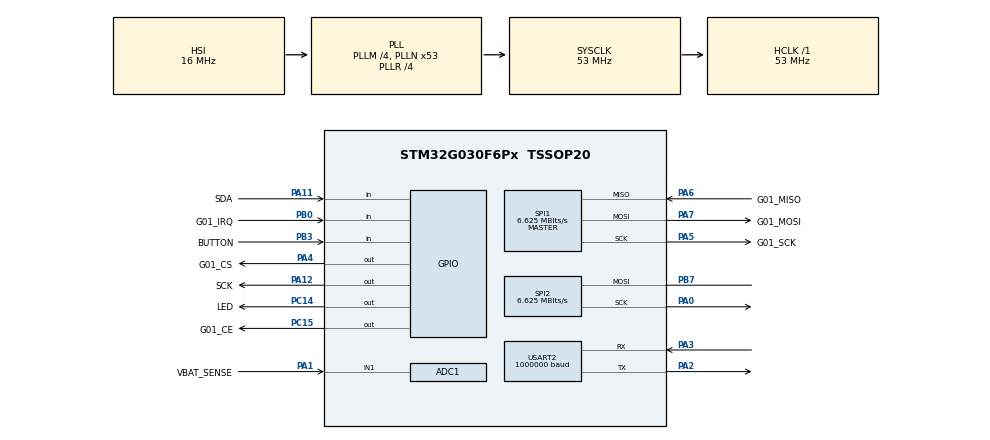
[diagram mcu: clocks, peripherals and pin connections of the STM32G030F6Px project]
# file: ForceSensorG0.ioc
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ADC1.Channel-1\#ChannelRegularConversion=ADC_CHANNEL_1
ADC1.NbrOfConversionFlag=1
ADC1.Rank-1\#ChannelRegularConversion=1
ADC1.SamplingTime-1\#ChannelRegularConversion=ADC_SAMPLINGTIME_COMMON_1
ADC1.SelectedChannel=ADC_CHANNEL_1
ADC1.master=1
Dma.Request0=SPI2_TX
Dma.Request1=SPI1_TX
Dma.SPI1_TX.1.Direction=DMA_MEMORY_TO_PERIPH
Dma.SPI1_TX.1.EventEnable=DISABLE
Dma.SPI1_TX.1.Instance=DMA1_Channel2
Dma.SPI1_TX.1.MemDataAlignment=DMA_MDATAALIGN_BYTE
Dma.SPI1_TX.1.MemInc=DMA_MINC_ENABLE
Dma.SPI1_TX.1.Mode=DMA_NORMAL
Dma.SPI1_TX.1.PeriphDataAlignment=DMA_PDATAALIGN_BYTE
Dma.SPI1_TX.1.PeriphInc=DMA_PINC_DISABLE
Dma.SPI1_TX.1.Polarity=HAL_DMAMUX_REQ_GEN_RISING
Dma.SPI1_TX.1.Priority=DMA_PRIORITY_LOW
Dma.SPI1_TX.1.RequestNumber=1
Dma.SPI1_TX.1.SignalID=NONE
Dma.SPI1_TX.1.SyncEnable=DISABLE
Dma.SPI1_TX.1.SyncPolarity=HAL_DMAMUX_SYNC_NO_EVENT
Dma.SPI1_TX.1.SyncRequestNumber=1
Dma.SPI1_TX.1.SyncSignalID=NONE
Dma.SPI2_TX.0.Direction=DMA_MEMORY_TO_PERIPH
Dma.SPI2_TX.0.EventEnable=DISABLE
Dma.SPI2_TX.0.Instance=DMA1_Channel1
Dma.SPI2_TX.0.MemDataAlignment=DMA_MDATAALIGN_BYTE
Dma.SPI2_TX.0.MemInc=DMA_MINC_ENABLE
Dma.SPI2_TX.0.Mode=DMA_CIRCULAR
Dma.SPI2_TX.0.PeriphDataAlignment=DMA_PDATAALIGN_BYTE
Dma.SPI2_TX.0.PeriphInc=DMA_PINC_DISABLE
Dma.SPI2_TX.0.Polarity=HAL_DMAMUX_REQ_GEN_RISING
Dma.SPI2_TX.0.Priority=DMA_PRIORITY_LOW
Dma.SPI2_TX.0.RequestNumber=1
Dma.SPI2_TX.0.SignalID=NONE
Dma.SPI2_TX.0.SyncEnable=DISABLE
Dma.SPI2_TX.0.SyncPolarity=HAL_DMAMUX_SYNC_NO_EVENT
Dma.SPI2_TX.0.SyncRequestNumber=1
Dma.SPI2_TX.0.SyncSignalID=NONE
Mcu.Family=STM32G0
Mcu.Name=STM32G030F6Px
Mcu.Package=TSSOP20
NVIC.DMA1_Channel1_IRQn=true\:0\:0\:false\:false\:true\:false\:true\:true
NVIC.DMA1_Channel2_3_IRQn=true\:0\:0\:false\:false\:true\:false\:true\:true
PA0.Mode=Simplex_Bidirectional_Master
PA0.Signal=SPI2_SCK
PA1.GPIO_Label=VBAT_SENSE
PA1.Mode=IN1
PA1.Signal=ADC1_IN1
PA11\ [PA9].GPIO_Label=SDA
PA11\ [PA9].GPIO_PuPd=GPIO_PULLUP
PA11\ [PA9].Signal=GPIO_Input
PA12\ [PA10].GPIO_Label=SCK
PA12\ [PA10].GPIO_Speed=GPIO_SPEED_FREQ_LOW
PA12\ [PA10].Signal=GPIO_Output
PA13.Mode=Serial_Wire
PA13.Signal=SYS_SWDIO
PA14-BOOT0.Mode=Serial_Wire
PA14-BOOT0.Signal=SYS_SWCLK
PA14-BOOT0__PA15.StandardMode=true
PA2.Mode=Asynchronous
PA2.Signal=USART2_TX
PA3.Mode=Asynchronous
PA3.Signal=USART2_RX
PA4.GPIO_Label=G01_CS
PA4.GPIO_Speed=GPIO_SPEED_FREQ_VERY_HIGH
PA4.PinState=GPIO_PIN_SET
PA4.Signal=GPIO_Output
PA5.GPIO_Label=G01_SCK
PA5.Mode=Full_Duplex_Master
PA5.Signal=SPI1_SCK
PA6.GPIO_Label=G01_MISO
PA6.Mode=Full_Duplex_Master
PA6.Signal=SPI1_MISO
PA7.GPIO_Label=G01_MOSI
PA7.Mode=Full_Duplex_Master
PA7.Signal=SPI1_MOSI
PB0.GPIO_Label=G01_IRQ
PB0.Signal=GPIO_Input
PB0__PB1__PB2__PA8.StandardMode=true
PB3.GPIO_Label=BUTTON
PB3.GPIO_PuPd=GPIO_PULLUP
PB3.Signal=GPIO_Input
PB3__PB4__PB5__PB6.StandardMode=true
PB7.Mode=Simplex_Bidirectional_Master
PB7.Signal=SPI2_MOSI
PB7__PB8.StandardMode=true
PC14-OSC32_IN\ (PC14).GPIO_Label=LED
PC14-OSC32_IN\ (PC14).PinState=GPIO_PIN_RESET
PC14-OSC32_IN\ (PC14).Signal=GPIO_Output
PC14-OSC32_IN\ (PC14)__PB9.StandardMode=true
PC15-OSC32_OUT\ (PC15).GPIO_Label=G01_CE
PC15-OSC32_OUT\ (PC15).PinState=GPIO_PIN_SET
PC15-OSC32_OUT\ (PC15).Signal=GPIO_Output
ProjectManager.HeapSize=0x200
ProjectManager.StackSize=0x400
ProjectManager.TargetToolchain=MDK-ARM V5.32
RCC.ADCFreq_Value=53000000
RCC.AHBFreq_Value=53000000
RCC.CortexFreq_Value=53000000
RCC.EXTERNAL_CLOCK_VALUE=12288000
RCC.HCLKFreq_Value=53000000
RCC.HSE_VALUE=8000000
RCC.HSI_VALUE=16000000
RCC.LSE_VALUE=32768
RCC.PLLM=RCC_PLLM_DIV4
RCC.PLLN=53
RCC.PLLR=RCC_PLLR_DIV4
RCC.SYSCLKFreq_VALUE=53000000
RCC.SYSCLKSource=RCC_SYSCLKSOURCE_PLLCLK
RCC.VCOOutputFreq_Value=212000000
SPI1.BaudRatePrescaler=SPI_BAUDRATEPRESCALER_8
SPI1.CalculateBaudRate=6.625 MBits/s
SPI1.Direction=SPI_DIRECTION_2LINES
SPI1.Mode=SPI_MODE_MASTER
SPI1.VirtualType=VM_MASTER
SPI2.BaudRatePrescaler=SPI_BAUDRATEPRESCALER_8
SPI2.CLKPhase=SPI_PHASE_2EDGE
SPI2.CLKPolarity=SPI_POLARITY_HIGH
SPI2.CalculateBaudRate=6.625 MBits/s
SPI2.Direction=SPI_DIRECTION_1LINE
SPI2.Mode=SPI_MODE_MASTER
SPI2.VirtualType=VM_MASTER
USART2.BaudRate=1000000
USART2.VirtualMode-Asynchronous=VM_ASYNC
board=custom

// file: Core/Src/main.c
/* USER CODE BEGIN Header */
/**
  ******************************************************************************
  * @file           : main.c
  * @brief          : Main program body
  ******************************************************************************
  * @attention
  *
  * Copyright (c) 2025 STMicroelectronics.
  * All rights reserved.
  *
  * This software is licensed under terms that can be found in the LICENSE file
  * in the root directory of this software component.
  * If no LICENSE file comes with this software, it is provided AS-IS.
  *
  ******************************************************************************
  */
/* USER CODE END Header */
#include "main.h"
#include "adc.h"
#include "dma.h"
#include "spi.h"
#include "usart.h"
#include "gpio.h"

/* USER CODE BEGIN Includes */
#include "system.h"

/* USER CODE END Includes */

void SystemClock_Config(void);

int main(void)
{

  /* MCU Configuration--------------------------------------------------------*/

  /* Reset of all peripherals, Initializes the Flash interface and the Systick. */
  HAL_Init();

  /* Configure the system clock */
  SystemClock_Config();

  /* Initialize all configured peripherals */
  MX_GPIO_Init();
  MX_DMA_Init();
  MX_SPI1_Init();
  MX_ADC1_Init();
  MX_SPI2_Init();
  MX_USART2_UART_Init();
  /* USER CODE BEGIN 2 */
  system_setup();
  /* USER CODE END 2 */

  /* Infinite loop */
  while (1)
  {

    /* USER CODE BEGIN 3 */
    system_loop();
  }
  /* USER CODE END 3 */
}

void SystemClock_Config(void)
{
  RCC_OscInitTypeDef RCC_OscInitStruct = {0};
  RCC_ClkInitTypeDef RCC_ClkInitStruct = {0};

  /** Configure the main internal regulator output voltage
  */
  HAL_PWREx_ControlVoltageScaling(PWR_REGULATOR_VOLTAGE_SCALE1);

  /** Initializes the RCC Oscillators according to the specified parameters
  * in the RCC_OscInitTypeDef structure.
  */
  RCC_OscInitStruct.OscillatorType = RCC_OSCILLATORTYPE_HSI;
  RCC_OscInitStruct.HSIState = RCC_HSI_ON;
  RCC_OscInitStruct.HSIDiv = RCC_HSI_DIV1;
  RCC_OscInitStruct.HSICalibrationValue = RCC_HSICALIBRATION_DEFAULT;
  RCC_OscInitStruct.PLL.PLLState = RCC_PLL_ON;
  RCC_OscInitStruct.PLL.PLLSource = RCC_PLLSOURCE_HSI;
  RCC_OscInitStruct.PLL.PLLM = RCC_PLLM_DIV4;
  RCC_OscInitStruct.PLL.PLLN = 53;
  RCC_OscInitStruct.PLL.PLLP = RCC_PLLP_DIV2;
  RCC_OscInitStruct.PLL.PLLR = RCC_PLLR_DIV4;
  if (HAL_RCC_OscConfig(&RCC_OscInitStruct) != HAL_OK)
  {
    Error_Handler();
  }

  /** Initializes the CPU, AHB and APB buses clocks
  */
  RCC_ClkInitStruct.ClockType = RCC_CLOCKTYPE_HCLK|RCC_CLOCKTYPE_SYSCLK
                              |RCC_CLOCKTYPE_PCLK1;
  RCC_ClkInitStruct.SYSCLKSource = RCC_SYSCLKSOURCE_PLLCLK;
  RCC_ClkInitStruct.AHBCLKDivider = RCC_SYSCLK_DIV1;
  RCC_ClkInitStruct.APB1CLKDivider = RCC_HCLK_DIV1;

  if (HAL_RCC_ClockConfig(&RCC_ClkInitStruct, FLASH_LATENCY_2) != HAL_OK)
  {
    Error_Handler();
  }
}

void Error_Handler(void)
{
  __disable_irq();
  while (1)
  {
  }
}
